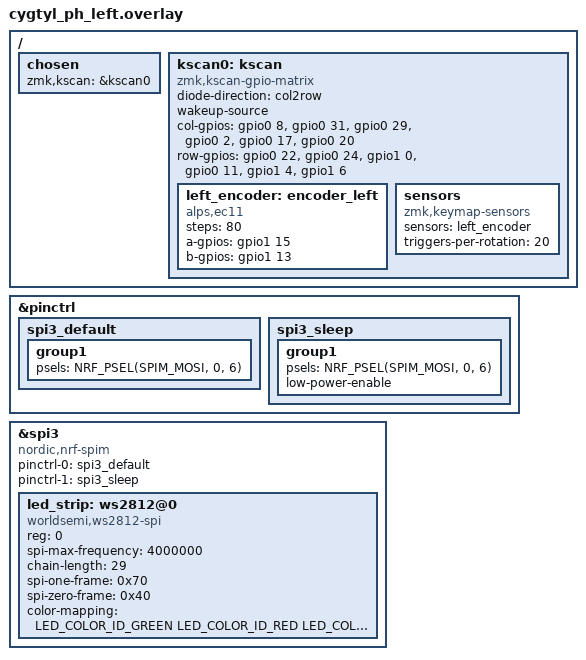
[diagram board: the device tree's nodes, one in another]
/*
 * Copyright (c) 2025 Noir Guo
 *
 * SPDX-License-Identifier: MIT
 */

#include "cygtyl.dtsi"

&pinctrl {
// Other pinctrl definitions for other hardware

    spi3_default: spi3_default {
        group1 {
            psels = <NRF_PSEL(SPIM_MOSI, 0, 6)>;
        };
    };

    spi3_sleep: spi3_sleep {
        group1 {
            psels = <NRF_PSEL(SPIM_MOSI, 0, 6)>;
            low-power-enable;
        };
    };
};

&spi3 {
    compatible = "nordic,nrf-spim";
    status = "okay";

    pinctrl-0 = <&spi3_default>;
    pinctrl-1 = <&spi3_sleep>;
    pinctrl-names = "default", "sleep";

    led_strip: ws2812@0 {
        compatible = "worldsemi,ws2812-spi";

        /* SPI */
        reg = <0>; /* ignored, but necessary for SPI bindings */
        spi-max-frequency = <4000000>;

        /* WS2812 */
        chain-length = <29>; /* arbitrary; change at will */
        spi-one-frame = <0x70>;
        spi-zero-frame = <0x40>;

        color-mapping = <
            LED_COLOR_ID_GREEN
            LED_COLOR_ID_RED
            LED_COLOR_ID_BLUE
        >;
    };
};

/{
    chosen {
        zmk,kscan = &kscan0;
    };


    kscan0: kscan {
        compatible = "zmk,kscan-gpio-matrix";
        diode-direction = "col2row";
        wakeup-source;

        col-gpios
            = <&gpio0 8 GPIO_ACTIVE_HIGH>
            , <&gpio0 31 GPIO_ACTIVE_HIGH>
            , <&gpio0 29 GPIO_ACTIVE_HIGH>
            , <&gpio0 2 GPIO_ACTIVE_HIGH>
            , <&gpio0 17 GPIO_ACTIVE_HIGH>
            , <&gpio0 20 GPIO_ACTIVE_HIGH>
            ;

        row-gpios
            = <&gpio0 22 (GPIO_ACTIVE_HIGH | GPIO_PULL_DOWN)>
            , <&gpio0 24 (GPIO_ACTIVE_HIGH | GPIO_PULL_DOWN)>
            , <&gpio1 0 (GPIO_ACTIVE_HIGH | GPIO_PULL_DOWN)>
            , <&gpio0 11 (GPIO_ACTIVE_HIGH | GPIO_PULL_DOWN)>
            , <&gpio1 4 (GPIO_ACTIVE_HIGH | GPIO_PULL_DOWN)>
            , <&gpio1 6 (GPIO_ACTIVE_HIGH | GPIO_PULL_DOWN)>
        ;

    left_encoder: encoder_left {
        compatible = "alps,ec11";
        steps = <80>;
        a-gpios = <&gpio1 15 (GPIO_ACTIVE_HIGH | GPIO_PULL_UP)>;
        b-gpios = <&gpio1 13 (GPIO_ACTIVE_HIGH | GPIO_PULL_UP)>;
        
        //a-gpios = <&gpio1 15 (GPIO_ACTIVE_HIGH | GPIO_PULL_DOWN)>;
        //b-gpios = <&gpio1 13 (GPIO_ACTIVE_HIGH | GPIO_PULL_DOWN)>;

        //a-gpios = <&gpio1 15 (GPIO_ACTIVE_LOW | GPIO_PULL_UP)>;
        //b-gpios = <&gpio1 13 (GPIO_ACTIVE_LOW | GPIO_PULL_UP)>;

        //a-gpios = <&gpio1 15 (GPIO_ACTIVE_LOW | GPIO_PULL_DOWN)>;
        //b-gpios = <&gpio1 13 (GPIO_ACTIVE_LOW | GPIO_PULL_DOWN)>;
        //status = "disabled";
        status = "okay";
    };

    sensors: sensors {
        compatible = "zmk,keymap-sensors";
        sensors = <&left_encoder>;
        //sensors = <&left_encoder &right_encoder>;
        triggers-per-rotation = <20>;
    };
    };
};
